# MCXN947_cm33_core0 register map
Vendor: nxp.com; File version: 1.0
CPU: CM33 r2p0, little endian, MPU, FPU, VTOR, 3 interrupt priority bits
Registers are 32-bit, read-write, reset 0x0 unless marked. A register's access mark holds for its fields unless they carry their own. Offsets are from the block's base; [hi:lo] are bit positions; 'fields as' and 'values as' point back to an identical list.

## PUF
Base 0x4002C000
Same registers: PUF_ALIAS1 0x4002D000, PUF_ALIAS2 0x4002E000, PUF_ALIAS3 0x4002F000
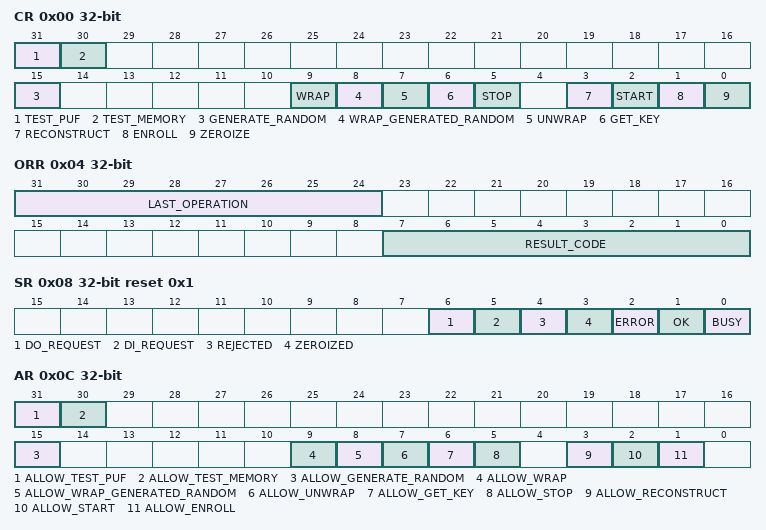
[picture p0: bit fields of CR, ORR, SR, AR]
0x00 CR — Control
  [31] TEST_PUF — Test PUF operation
  [30] TEST_MEMORY — Test memory operation
  [15] GENERATE_RANDOM — Generate Random operation
  [9] WRAP — Wrap operation
  [8] WRAP_GENERATED_RANDOM — Wrap Generated Random operation
  [7] UNWRAP — Unwrap operation
  [6] GET_KEY — Get Key operation
  [5] STOP — Stop operation
  [3] RECONSTRUCT — Reconstruct operation
  [2] START — Start operation
  [1] ENROLL — Enroll operation
  [0] ZEROIZE — Zeroize operation
0x04 ORR ro — Operation Result
  [31:24] LAST_OPERATION — Last operation type
    0=LO_PROGRESS (Indicates that the operation is in progress.); 1=LO_ENROLL (Indicates that the last operation was Enroll.); 2=LO_START (Indicates that the last operation was Start.); 3=LO_RECONSTRUCT (Indicates that the last operation was Reconstruct); 5=LO_STOP (Indicates that the last operation was Stop.); 6=LO_GET_KEY (Indicates that the last operation was Get Key.); 7=LO_UNWRAP (Indicates that the last operation was Unwrap.); 8=LO_WRAP_GEN_RND (Indicates that the last operation was Wrap Generated Random.); 9=LO_WRAP (Indicates that the last operation was Wrap.); 15=LO_GEN_RND (Indicates that the last operation was Generate Random.); 30=LO_TEST_MEMORY (Indicates that the last operation was Test Memory.); 31=LO_TEST_PUF (Indicates that the last operation was Test PUF.); 32=LO_INITIALIZATION (Indicates that the last operation was Initialization.); 47=LO_ZEROIZE (Indicates that the last operation was Zeroize.)
  [7:0] RESULT_CODE — Result code of last operation
    0=OK (Indicates that the last operation was successful or operation is in progress.); 240=ERR_PRODUCT (Indicates that the AC is not for the current product/version.); 241=ERR_PRODUCT_PH2 (Indicates that the AC in the second phase is not for the current product/version.); 242=ERR_TRANSFER (Indicates that the AC is corrupted.); 243=ERR_TRANSFER_PH2 (Indicates that the AC in the second phase is corrupted.); 244=ERR_AUTH (Indicates that the authentication of the provided AC failed.); 245=ERR_AUTH_PH2 (Indicates that the authentication of the provided AC failed in the second phase.); 246=ERR_PUF_QUALITY (Indicates that the SRAM PUF quality verification fails.); 247=ERR_CONTEXT (Indicates that the incorrect or unsupported context is provided.); 248=ERR_DESTINATION (Indicates that a data destination was set that is not allowed according to other settings and the current PUF state.); 255=FAILURE (Indicates that the PUF SRAM access has failed.)
0x08 SR reset 0x1 — Status
  [6] DO_REQUEST ro — Indicates the request for data out transfer via the DOR register
  [5] DI_REQUEST ro — Indicates the request for data in transfer via the DIR register
  [4] REJECTED write-1-clears — Operation rejected
  [3] ZEROIZED ro — Zeroized or Locked state
  [2] ERROR ro — Last operation failed
  [1] OK ro — Last operation successful
  [0] BUSY ro — Operation in progress
0x0C AR ro — Allow
  [31] ALLOW_TEST_PUF — Test PUF operation
    0=DISABLE (Test PUF operation is not allowed); 1=ENABLE (Test PUF operation is allowed)
  [30] ALLOW_TEST_MEMORY
    0=DISABLE (Indicates that the Test Memory operation is not allowed); 1=ENABLE (Indicates that the Test Memory operation is allowed)
  [15] ALLOW_GENERATE_RANDOM — Generate Random operation
    0=DISABLE (Indicates that the Generate Random operation is not allowed); 1=ENABLE (Indicates that the Generate Random operation is allowed)
  [9] ALLOW_WRAP — Wrap operation
    0=DISABLE (Indicates that the Wrap operation is not allowed); 1=ENABLE (Indicates that the Wrap operation is allowed)
  [8] ALLOW_WRAP_GENERATED_RANDOM — Wrap Generated Random operation
    0=DISABLE (Indicates that the Wrap Generated Random operation is not allowed); 1=ENABLE (Indicates that the Wrap Generated Random operation is allowed)
  [7] ALLOW_UNWRAP — Unwrap operation
    0=DISABLE (Indicates that the Unwrap operation is not allowed); 1=ENABLE (Indicates that the Unwrap operation is allowed)
  [6] ALLOW_GET_KEY — Get Key operation
    0=DISABLE (Indicates that the Get Key operation is not allowed); 1=ENABLE (Indicates that the Get Key operation is allowed)
  [5] ALLOW_STOP — Stop operation
    0=DISABLE (Indicates that the Stop operation is not allowed); 1=ENABLE (Indicates that the Stop operation is allowed)
  [3] ALLOW_RECONSTRUCT — Reconstruct operation
    0=DISABLE (Indicates that the Reconstruct operation is not allowed); 1=ENABLE (Indicates that the Reconstruct operation is allowed)
  [2] ALLOW_START — Start operation
    0=DISABLE (Indicates that the Start operation is not allowed); 1=ENABLE (Indicates that the Start operation is allowed)
  [1] ALLOW_ENROLL — Enroll operation
    0=DISABLE (Indicates that the Enroll operation is not allowed); 1=ENABLE (Indicates that the Enroll operation is allowed)
0x10 IER — Interrupt Enable
  [0] INT_EN — Interrupt enable
    0=DISABLE (Disables all PUF interrupts); 1=ENABLE (Enables all PUF interrupts that are enabled in the Interrupt Mask register)
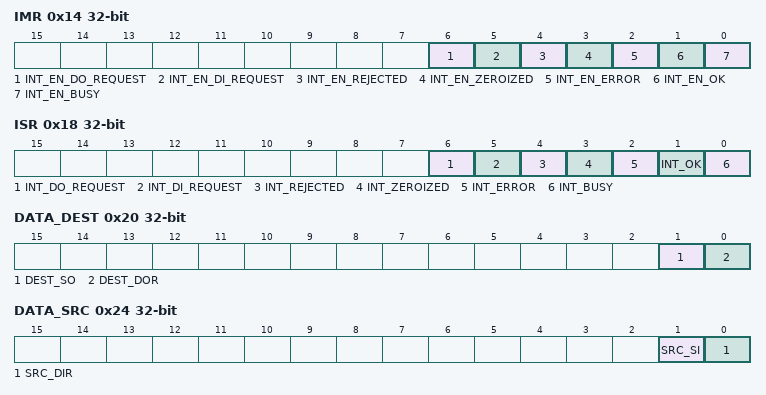
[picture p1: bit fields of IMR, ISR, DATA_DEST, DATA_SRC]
0x14 IMR — Interrupt Mask
  [6] INT_EN_DO_REQUEST — Data out request interrupt
  [5] INT_EN_DI_REQUEST — Data in request interrupt
  [4] INT_EN_REJECTED — Rejected interrupt
  [3] INT_EN_ZEROIZED — Zeroized interrupt
  [2] INT_EN_ERROR — Error interrupt
  [1] INT_EN_OK — Ok interrupt
  [0] INT_EN_BUSY — Busy interrupt
0x18 ISR write-1-clears — Interrupt Status
  [6] INT_DO_REQUEST write-1-clears — Positive edge occurred on do_request
  [5] INT_DI_REQUEST write-1-clears — Positive edge occurred on di_request
  [4] INT_REJECTED write-1-clears — Positive edge occurred on Rejected
  [3] INT_ZEROIZED write-1-clears — Positive edge occurred on Zeroized
  [2] INT_ERROR write-1-clears — Positive edge occurred on Error
  [1] INT_OK write-1-clears — Positive edge occurred on Ok
  [0] INT_BUSY write-1-clears — Negative edge occurred on Busy
0x20 DATA_DEST — Data Destination
  [1] DEST_SO — Key available to ELS
  [0] DEST_DOR — Key available via the DOR register
0x24 DATA_SRC — Data Source
  [1] SRC_SI — Data provided via the SI interface
  [0] SRC_DIR — Data provided via the DIR register
0xA0 DIR wo — Data Input
  [31:0] DI — Input data
0xA8 DOR ro — Data Output
  [31:0] DO — Output data
0xC0 MISC reset 0x1 — Miscellaneous
  [0] DATA_ENDIANNESS — Defines the endianness of data in DIR and DOR:
    0=DISABLE (Little endian); 1=ENABLE (Big endian (default))
0xD0 IF_SR write-1-clears — Interface Status
  [0] APB_ERROR write-1-clears
0xDC PSR ro reset 0xF — PUF Score
  [3:0] PUF_SCORE — Provides the PUF score obtained during the last Test PUF, Enroll or Start operation.
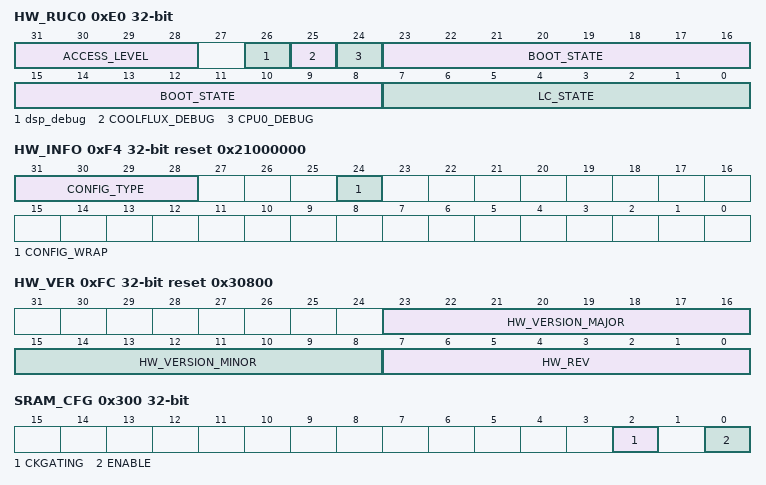
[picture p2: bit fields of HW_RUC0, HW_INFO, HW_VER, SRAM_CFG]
0xE0 HW_RUC0 ro reset not defined — Hardware Restrict User Context 0
  [31:28] ACCESS_LEVEL — Restrict the key access based on TrustZone security level
  [26] dsp_debug — DSP debug status.
  [25] COOLFLUX_DEBUG — Disable key access when debugger is attached to COOLFLUX after power-up
  [24] CPU0_DEBUG — Disable key access when debugger is attached to CPU0 after power-up
  [23:8] BOOT_STATE — Temporal boot state
  [7:0] LC_STATE — Life cycle state based restrictions
    3=oem_open (OEM Develop); 7=oem_secure_world (OEM Develop 2); 15=oem_closed (OEM In-field); 31=oem_field_return; 63=field_return_nxp (NXP Field Return/Failure Analysis); 207=oem_locked (In-field Locked); 255=oem_shredded (Bricked)
0xE4 HW_RUC1 ro — Hardware Restrict User Context 1
  [31:0] APP_CTX — Application customizable context
0xF4 HW_INFO ro reset 0x21000000 — Hardware Information
  [31:28] CONFIG_TYPE — PUF configuration
    1=SAFE (Indicates that PUF configuration is Safe.); 2=PLUS (Indicates that PUF configuration is Plus.)
  [24] CONFIG_WRAP — Wrap configuration
    0=ENABLE (Indicates that Wrap is not included); 1=DISABLE (Indicates that Wrap is included)
0xF8 HW_ID ro reset 0x21042000 — Hardware Identifier
  [31:0] HW_ID — Provides the hardware identifier
0xFC HW_VER ro reset 0x30800 — Hardware Version
  [23:16] HW_VERSION_MAJOR — Provides the hardware version, major part
  [15:8] HW_VERSION_MINOR — Provides the hardware version, minor part
  [7:0] HW_REV — Provides the hardware version, patch part
0x300 SRAM_CFG — SRAM Configuration
  [2] CKGATING — PUF SRAM Clock Gating control
    1=ENABLE (Enabled)
  [0] ENABLE — PUF SRAM Controller activation
    1=ENABLE (Enabled)
0x304 SRAM_STATUS ro reset 0x1 — Status
  [0] READY — PUF SRAM Controller State
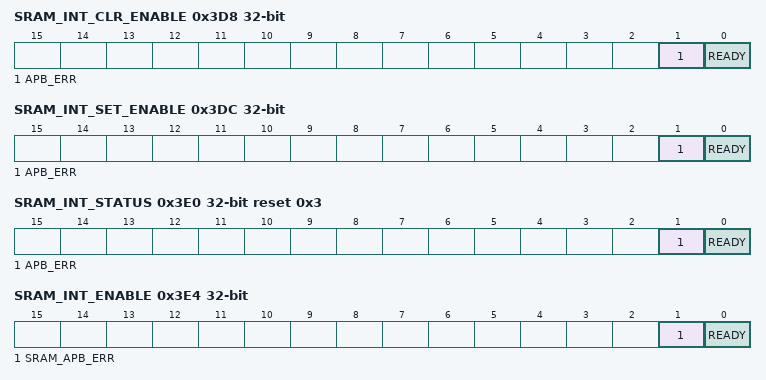
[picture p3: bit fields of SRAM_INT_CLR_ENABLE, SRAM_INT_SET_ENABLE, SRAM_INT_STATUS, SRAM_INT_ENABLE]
0x3D8 SRAM_INT_CLR_ENABLE wo — Interrupt Enable Clear
  [1] APB_ERR — APB_ERR Interrupt Enable clear
  [0] READY — READY Interrupt Enable clear
0x3DC SRAM_INT_SET_ENABLE wo — Interrupt Enable Set
  [1] APB_ERR — APB_ERR Interrupt Enable set
  [0] READY — READY Interrupt Enable set
0x3E0 SRAM_INT_STATUS reset 0x3 — Interrupt Status
  [1] APB_ERR ro — APB_ERR Interrupt Status
  [0] READY ro — READY Interrupt Status
0x3E4 SRAM_INT_ENABLE — Interrupt Enable
  [1] SRAM_APB_ERR ro — APB_ERR Interrupt Enable
    1=ENABLE (Enabled)
  [0] READY ro — READY Interrupt Enable
    1=ENABLE (Enabled)
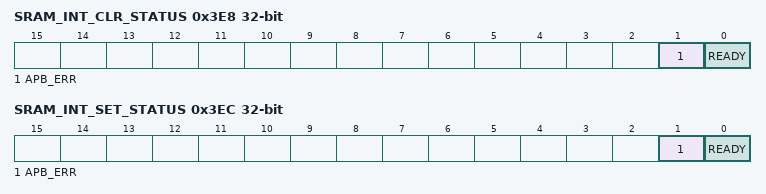
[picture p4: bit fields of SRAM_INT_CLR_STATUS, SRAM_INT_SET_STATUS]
0x3E8 SRAM_INT_CLR_STATUS wo — Interrupt Status Clear
  [1] APB_ERR — APB_ERR Interrupt Status Clear
    0=no_effect; 1=ENABLE (Clears the APB_ERR bit field in register INT_STATUS. Automatically reset by the Hardware)
  [0] READY — READY Interrupt Status clear
0x3EC SRAM_INT_SET_STATUS wo — Interrupt Status set
  [1] APB_ERR — APB_ERR Interrupt Status Set
    values as SRAM_INT_CLR_STATUS.APB_ERR
  [0] READY — READY Interrupt Status set
